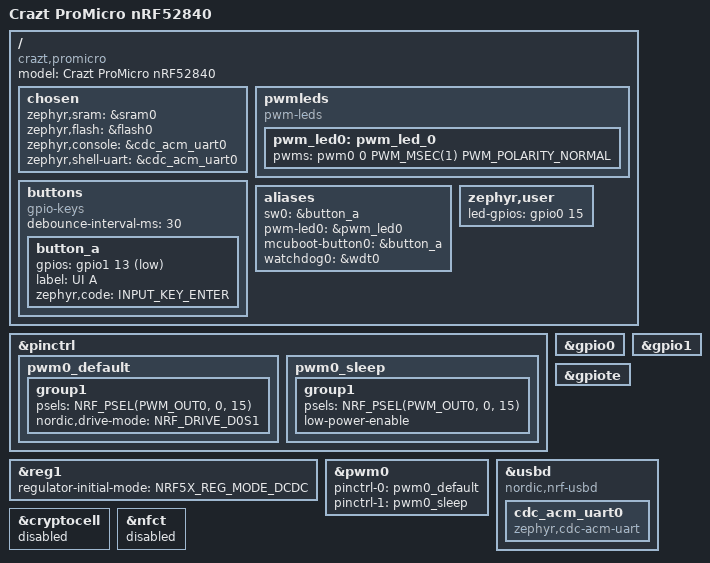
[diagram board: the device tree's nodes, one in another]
// Copyright (c) 2026
// SPDX-License-Identifier: Apache-2.0

#include <nordic/nrf52840_qiaa.dtsi>
#include <zephyr/dt-bindings/input/input-event-codes.h>

&pinctrl {
	pwm0_default: pwm0_default {
		group1 {
			psels = <NRF_PSEL(PWM_OUT0, 0, 15)>;
			nordic,drive-mode = <NRF_DRIVE_D0S1>;
		};
	};

	pwm0_sleep: pwm0_sleep {
		group1 {
			psels = <NRF_PSEL(PWM_OUT0, 0, 15)>;
			low-power-enable;
		};
	};
};

/ {
	model = "Crazt ProMicro nRF52840";
	compatible = "crazt,promicro";

	chosen {
		zephyr,sram = &sram0;
		zephyr,flash = &flash0;
		zephyr,console = &cdc_acm_uart0;
		zephyr,shell-uart = &cdc_acm_uart0;
	};

	pwmleds: pwmleds {
		compatible = "pwm-leds";
		pwm_led0: pwm_led_0 {
			pwms = <&pwm0 0 PWM_MSEC(1) PWM_POLARITY_NORMAL>;
		};
	};

	buttons: buttons {
		compatible = "gpio-keys";
		debounce-interval-ms = <30>;
		button_a: button_a {
			gpios = <&gpio1 13 (GPIO_PULL_UP | GPIO_ACTIVE_LOW)>;
			label = "UI A";
			zephyr,code = <INPUT_KEY_ENTER>;
		};
	};

	aliases {
		sw0 = &button_a;
		pwm-led0 = &pwm_led0;
		mcuboot-button0 = &button_a;
		watchdog0 = &wdt0;
	};

	zephyr,user {
		led-gpios = <&gpio0 15 GPIO_OPEN_SOURCE>;
	};
};

&reg1 {
	regulator-initial-mode = <NRF5X_REG_MODE_DCDC>;
};

&gpio0 {
	status = "okay";
};

&gpio1 {
	status = "okay";
};

&gpiote {
	status = "okay";
};

&pwm0 {
	status = "okay";
	pinctrl-0 = <&pwm0_default>;
	pinctrl-1 = <&pwm0_sleep>;
	pinctrl-names = "default", "sleep";
};

zephyr_udc0: &usbd {
	compatible = "nordic,nrf-usbd";
	status = "okay";
	cdc_acm_uart0: cdc_acm_uart0 {
		compatible = "zephyr,cdc-acm-uart";
	};
};

&cryptocell {
	status = "disabled";
};

&nfct {
	status = "disabled";
};
